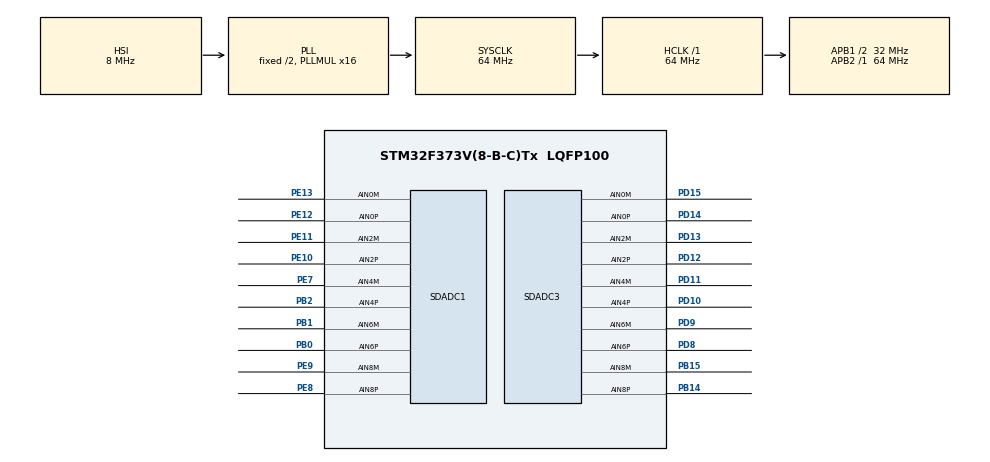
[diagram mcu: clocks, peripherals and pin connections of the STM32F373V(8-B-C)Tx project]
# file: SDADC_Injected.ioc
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Dma.Request0=SDADC1
Dma.Request1=SDADC3
Dma.SDADC1.0.Direction=DMA_PERIPH_TO_MEMORY
Dma.SDADC1.0.Instance=DMA2_Channel3
Dma.SDADC1.0.MemDataAlignment=DMA_MDATAALIGN_WORD
Dma.SDADC1.0.MemInc=DMA_MINC_ENABLE
Dma.SDADC1.0.Mode=DMA_CIRCULAR
Dma.SDADC1.0.PeriphDataAlignment=DMA_PDATAALIGN_HALFWORD
Dma.SDADC1.0.PeriphInc=DMA_PINC_DISABLE
Dma.SDADC1.0.Priority=DMA_PRIORITY_HIGH
Dma.SDADC3.1.Direction=DMA_PERIPH_TO_MEMORY
Dma.SDADC3.1.Instance=DMA2_Channel5
Dma.SDADC3.1.MemDataAlignment=DMA_MDATAALIGN_WORD
Dma.SDADC3.1.MemInc=DMA_MINC_ENABLE
Dma.SDADC3.1.Mode=DMA_CIRCULAR
Dma.SDADC3.1.PeriphDataAlignment=DMA_PDATAALIGN_HALFWORD
Dma.SDADC3.1.PeriphInc=DMA_PINC_DISABLE
Dma.SDADC3.1.Priority=DMA_PRIORITY_HIGH
FREERTOS.Tasks01=defaultTask,0,128,StartDefaultTask,Default,NULL,Dynamic,NULL,NULL
Mcu.Family=STM32F3
Mcu.Name=STM32F373V(8-B-C)Tx
Mcu.Package=LQFP100
NVIC.DMA2_Channel3_IRQn=true\:0\:0\:false\:false\:true\:true\:false\:true
NVIC.DMA2_Channel5_IRQn=true\:0\:0\:false\:false\:true\:true\:false\:true
NVIC.PriorityGroup=NVIC_PRIORITYGROUP_4
PA13.Mode=Serial_Wire
PA13.Signal=SYS_JTMS-SWDIO
PA14.Mode=Serial_Wire
PA14.Signal=SYS_JTCK-SWCLK
PB0.Mode=IN6-Differential
PB0.Signal=SDADC1_AIN6P
PB1.Mode=IN6-Differential
PB1.Signal=SDADC1_AIN6M
PB14.Mode=IN8-Differential
PB14.Signal=SDADC3_AIN8P
PB15.Mode=IN8-Differential
PB15.Signal=SDADC3_AIN8M
PB2.Mode=IN4-Differential
PB2.Signal=SDADC1_AIN4P
PD10.Mode=IN4-Differential
PD10.Signal=SDADC3_AIN4P
PD11.Mode=IN4-Differential
PD11.Signal=SDADC3_AIN4M
PD12.Mode=IN2-Differential
PD12.Signal=SDADC3_AIN2P
PD13.Mode=IN2-Differential
PD13.Signal=SDADC3_AIN2M
PD14.Mode=IN0-Differential
PD14.Signal=SDADC3_AIN0P
PD15.Mode=IN0-Differential
PD15.Signal=SDADC3_AIN0M
PD8.Mode=IN6-Differential
PD8.Signal=SDADC3_AIN6P
PD9.Mode=IN6-Differential
PD9.Signal=SDADC3_AIN6M
PE10.Mode=IN2-Differential
PE10.Signal=SDADC1_AIN2P
PE11.Mode=IN2-Differential
PE11.Signal=SDADC1_AIN2M
PE12.Mode=IN0-Differential
PE12.Signal=SDADC1_AIN0P
PE13.Mode=IN0-Differential
PE13.Signal=SDADC1_AIN0M
PE7.Mode=IN4-Differential
PE7.Signal=SDADC1_AIN4M
PE8.Mode=IN8-Differential
PE8.Signal=SDADC1_AIN8P
PE9.Mode=IN8-Differential
PE9.Signal=SDADC1_AIN8M
ProjectManager.HeapSize=0x200
ProjectManager.StackSize=0x400
ProjectManager.TargetToolchain=STM32CubeIDE
RCC.AHBFreq_Value=64000000
RCC.APB1CLKDivider=RCC_HCLK_DIV2
RCC.APB1Freq_Value=32000000
RCC.APB1TimFreq_Value=64000000
RCC.APB2Freq_Value=64000000
RCC.APB2TimFreq_Value=64000000
RCC.CortexFreq_Value=64000000
RCC.HCLKFreq_Value=64000000
RCC.HSE_VALUE=8000000
RCC.HSI_VALUE=8000000
RCC.LSE_VALUE=32768
RCC.PLLMUL=RCC_PLL_MUL16
RCC.SDADCPresc=RCC_SDADCSYSCLK_DIV16
RCC.SYSCLKFreq_VALUE=64000000
RCC.SYSCLKSource=RCC_SYSCLKSOURCE_PLLCLK
RCC.USBFreq_Value=64000000
SDADC1.EnableInjectedConversion=ENABLE
SDADC1.InjNumberOfConversion=5
SDADC1.InjectedChannel-0\#ChannelInjectedConversion=SDADC_CHANNEL_0
SDADC1.InjectedChannel-1\#ChannelInjectedConversion=SDADC_CHANNEL_2
SDADC1.InjectedChannel-2\#ChannelInjectedConversion=SDADC_CHANNEL_4
SDADC1.InjectedChannel-3\#ChannelInjectedConversion=SDADC_CHANNEL_6
SDADC1.InjectedChannel-5\#ChannelInjectedConversion=SDADC_CHANNEL_8
SDADC1.InjectedChannelsSelection=SDADC_CHANNEL_0|SDADC_CHANNEL_2|SDADC_CHANNEL_4|SDADC_CHANNEL_6|SDADC_CHANNEL_8
SDADC1.InjectedConfIndex-0\#ChannelInjectedConversion=SDADC_CONF_INDEX_0
SDADC1.InjectedConfIndex-1\#ChannelInjectedConversion=SDADC_CONF_INDEX_0
SDADC1.InjectedConfIndex-2\#ChannelInjectedConversion=SDADC_CONF_INDEX_0
SDADC1.InjectedConfIndex-3\#ChannelInjectedConversion=SDADC_CONF_INDEX_0
SDADC1.InjectedConfIndex-5\#ChannelInjectedConversion=SDADC_CONF_INDEX_0
SDADC1.InjectedContinuousMode=SDADC_CONTINUOUS_CONV_ON
SDADC1.InjectedRank-0\#ChannelInjectedConversion=1
SDADC1.InjectedRank-1\#ChannelInjectedConversion=2
SDADC1.InjectedRank-2\#ChannelInjectedConversion=3
SDADC1.InjectedRank-3\#ChannelInjectedConversion=4
SDADC1.InjectedRank-5\#ChannelInjectedConversion=5
SDADC1.NbrOfConversionFlag=1
SDADC3.EnableInjectedConversion=ENABLE
SDADC3.InjNumberOfConversion=5
SDADC3.InjectedChannel-0\#ChannelInjectedConversion=SDADC_CHANNEL_0
SDADC3.InjectedChannel-1\#ChannelInjectedConversion=SDADC_CHANNEL_2
SDADC3.InjectedChannel-2\#ChannelInjectedConversion=SDADC_CHANNEL_4
SDADC3.InjectedChannel-3\#ChannelInjectedConversion=SDADC_CHANNEL_6
SDADC3.InjectedChannel-5\#ChannelInjectedConversion=SDADC_CHANNEL_8
SDADC3.InjectedChannelsSelection=SDADC_CHANNEL_0|SDADC_CHANNEL_2|SDADC_CHANNEL_4|SDADC_CHANNEL_6|SDADC_CHANNEL_8
SDADC3.InjectedConfIndex-0\#ChannelInjectedConversion=SDADC_CONF_INDEX_0
SDADC3.InjectedConfIndex-1\#ChannelInjectedConversion=SDADC_CONF_INDEX_0
SDADC3.InjectedConfIndex-2\#ChannelInjectedConversion=SDADC_CONF_INDEX_0
SDADC3.InjectedConfIndex-3\#ChannelInjectedConversion=SDADC_CONF_INDEX_0
SDADC3.InjectedConfIndex-5\#ChannelInjectedConversion=SDADC_CONF_INDEX_0
SDADC3.InjectedContinuousMode=SDADC_CONTINUOUS_CONV_ON
SDADC3.InjectedRank-0\#ChannelInjectedConversion=1
SDADC3.InjectedRank-1\#ChannelInjectedConversion=2
SDADC3.InjectedRank-2\#ChannelInjectedConversion=3
SDADC3.InjectedRank-3\#ChannelInjectedConversion=4
SDADC3.InjectedRank-5\#ChannelInjectedConversion=5
SDADC3.NbrOfConversionFlag=1
VP_FREERTOS_VS_CMSIS_V1.Mode=CMSIS_V1
VP_SDADC1_CONF0.Mode=ConfigZero
VP_SDADC3_CONF0.Mode=ConfigZero
board=custom

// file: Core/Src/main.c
/* USER CODE BEGIN Header */
/**
  ******************************************************************************
  * @file           : main.c
  * @brief          : Main program body
  ******************************************************************************
  * @attention
  *
  * <h2><center>&copy; Copyright (c) 2020 STMicroelectronics.
  * All rights reserved.</center></h2>
  *
  * This software component is licensed by ST under BSD 3-Clause license,
  * the "License"; You may not use this file except in compliance with the
  * License. You may obtain a copy of the License at:
  *                        opensource.org/licenses/BSD-3-Clause
  *
  ******************************************************************************
  */
/* USER CODE END Header */
#include "main.h"
#include "cmsis_os.h"
#include "dma.h"
#include "sdadc.h"
#include "gpio.h"

void SystemClock_Config(void);
void MX_FREERTOS_Init(void);

int main(void)
{

  /* MCU Configuration--------------------------------------------------------*/

  /* Reset of all peripherals, Initializes the Flash interface and the Systick. */
  HAL_Init();

  /* Configure the system clock */
  SystemClock_Config();

  /* Initialize all configured peripherals */
  MX_GPIO_Init();
  MX_DMA_Init();
  MX_SDADC1_Init();
  MX_SDADC3_Init();

  /* Call init function for freertos objects (in freertos.c) */
  MX_FREERTOS_Init();
  /* Start scheduler */
  osKernelStart();

  /* We should never get here as control is now taken by the scheduler */
  /* Infinite loop */
  while (1)
  {

  }
}

void SystemClock_Config(void)
{
  RCC_OscInitTypeDef RCC_OscInitStruct = {0};
  RCC_ClkInitTypeDef RCC_ClkInitStruct = {0};
  RCC_PeriphCLKInitTypeDef PeriphClkInit = {0};

  /** Initializes the RCC Oscillators according to the specified parameters
  * in the RCC_OscInitTypeDef structure.
  */
  RCC_OscInitStruct.OscillatorType = RCC_OSCILLATORTYPE_HSI;
  RCC_OscInitStruct.HSIState = RCC_HSI_ON;
  RCC_OscInitStruct.HSICalibrationValue = RCC_HSICALIBRATION_DEFAULT;
  RCC_OscInitStruct.PLL.PLLState = RCC_PLL_ON;
  RCC_OscInitStruct.PLL.PLLSource = RCC_PLLSOURCE_HSI;
  RCC_OscInitStruct.PLL.PLLMUL = RCC_PLL_MUL16;
  if (HAL_RCC_OscConfig(&RCC_OscInitStruct) != HAL_OK)
  {
    Error_Handler();
  }
  /** Initializes the CPU, AHB and APB buses clocks
  */
  RCC_ClkInitStruct.ClockType = RCC_CLOCKTYPE_HCLK|RCC_CLOCKTYPE_SYSCLK
                              |RCC_CLOCKTYPE_PCLK1|RCC_CLOCKTYPE_PCLK2;
  RCC_ClkInitStruct.SYSCLKSource = RCC_SYSCLKSOURCE_PLLCLK;
  RCC_ClkInitStruct.AHBCLKDivider = RCC_SYSCLK_DIV1;
  RCC_ClkInitStruct.APB1CLKDivider = RCC_HCLK_DIV2;
  RCC_ClkInitStruct.APB2CLKDivider = RCC_HCLK_DIV1;

  if (HAL_RCC_ClockConfig(&RCC_ClkInitStruct, FLASH_LATENCY_2) != HAL_OK)
  {
    Error_Handler();
  }
  PeriphClkInit.PeriphClockSelection = RCC_PERIPHCLK_SDADC;
  PeriphClkInit.SdadcClockSelection = RCC_SDADCSYSCLK_DIV16;
  if (HAL_RCCEx_PeriphCLKConfig(&PeriphClkInit) != HAL_OK)
  {
    Error_Handler();
  }
  HAL_PWREx_EnableSDADC(PWR_SDADC_ANALOG1);
  HAL_PWREx_EnableSDADC(PWR_SDADC_ANALOG3);
}

void Error_Handler(void)
{
}

/************************ (C) COPYRIGHT STMicroelectronics *****END OF FILE****/

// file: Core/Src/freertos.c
/* USER CODE BEGIN Header */
/**
  ******************************************************************************
  * File Name          : freertos.c
  * Description        : Code for freertos applications
  ******************************************************************************
  * @attention
  *
  * <h2><center>&copy; Copyright (c) 2020 STMicroelectronics.
  * All rights reserved.</center></h2>
  *
  * This software component is licensed by ST under Ultimate Liberty license
  * SLA0044, the "License"; You may not use this file except in compliance with
  * the License. You may obtain a copy of the License at:
  *                             www.st.com/SLA0044
  *
  ******************************************************************************
  */
/* USER CODE END Header */

#include "FreeRTOS.h"
#include "task.h"
#include "main.h"
#include "cmsis_os.h"

/* USER CODE BEGIN Includes */
#include "stm32f3xx_it.h"
#include "sdadc.h"
/* USER CODE END Includes */

osThreadId defaultTaskHandle;

void StartDefaultTask(void const * argument);

void MX_FREERTOS_Init(void); /* (MISRA C 2004 rule 8.1) */

/* GetIdleTaskMemory prototype (linked to static allocation support) */
void vApplicationGetIdleTaskMemory( StaticTask_t **ppxIdleTaskTCBBuffer, StackType_t **ppxIdleTaskStackBuffer, uint32_t *pulIdleTaskStackSize );

/* USER CODE BEGIN GET_IDLE_TASK_MEMORY */
static StaticTask_t xIdleTaskTCBBuffer;
static StackType_t xIdleStack[configMINIMAL_STACK_SIZE];

void vApplicationGetIdleTaskMemory( StaticTask_t **ppxIdleTaskTCBBuffer, StackType_t **ppxIdleTaskStackBuffer, uint32_t *pulIdleTaskStackSize )
{
  *ppxIdleTaskTCBBuffer = &xIdleTaskTCBBuffer;
  *ppxIdleTaskStackBuffer = &xIdleStack[0];
  *pulIdleTaskStackSize = configMINIMAL_STACK_SIZE;
  /* place for user code */
}
/* USER CODE END GET_IDLE_TASK_MEMORY */

void MX_FREERTOS_Init(void) {

  /* Create the thread(s) */
  /* definition and creation of defaultTask */
  osThreadDef(defaultTask, StartDefaultTask, osPriorityNormal, 0, 128);
  defaultTaskHandle = osThreadCreate(osThread(defaultTask), NULL);

}

/* USER CODE BEGIN Header_StartDefaultTask */
static uint32_t     SDADC1_DegitalValue[5];
static uint32_t     SDADC3_DegitalValue[5];
/**
  * @brief  Function implementing the defaultTask thread.
  * @param  argument: Not used
  * @retval None
  */
/* USER CODE END Header_StartDefaultTask */
void StartDefaultTask(void const * argument)
{
  /* USER CODE BEGIN StartDefaultTask */
  /* Infinite loop */
  for(;;)
  {
	if(HAL_SDADC_InjectedStart_DMA(&hsdadc3,SDADC3_DegitalValue,5) == HAL_OK)
	{
		while(IsFinishDMA2_Channel5 == 0)
			osDelay(1);//等待DMA转换完成
		IsFinishDMA2_Channel5 = 0;
		HAL_SDADC_InjectedStop_DMA(&hsdadc3);
	}

	if(HAL_SDADC_InjectedStart_DMA(&hsdadc1,SDADC1_DegitalValue,5) == HAL_OK)
	{
		while(IsFinishDMA2_Channel3 == 0)
			osDelay(1);//等待DMA转换完成
		IsFinishDMA2_Channel3 = 0;
		HAL_SDADC_InjectedStop_DMA(&hsdadc1);
	}
    osDelay(1);
  }
  /* USER CODE END StartDefaultTask */
}

/************************ (C) COPYRIGHT STMicroelectronics *****END OF FILE****/
